# MDR1986VE81 register map
Vendor: Milandr; Series: ARMCM4; File version: 2.0
CPU: CM4 r0p0, little endian, MPU, FPU, 3 interrupt priority bits
Registers are 32-bit, read-write, reset 0x0 unless marked. A register's access mark holds for its fields unless they carry their own. Offsets are from the block's base; [hi:lo] are bit positions; {n}, {i} and the like mark numbered series; 'fields as' and 'values as' point back to an identical list.

## MDR_SRAM — OTP_SRAM Memory Control
Base 0x40006000
0x00 KEY — Unlock block register
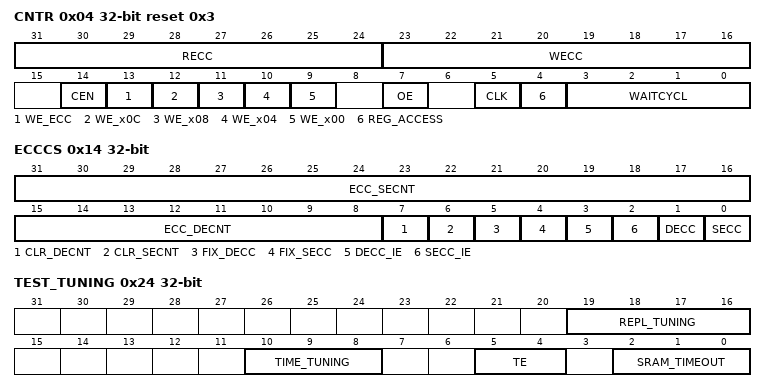
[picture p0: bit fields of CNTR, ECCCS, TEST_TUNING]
0x04 CNTR reset 0x3 — Control register
  [31:24] RECC — ECC after read with RDATA
  [23:16] WECC — ECC for write with WDATA
  [14] CEN — CE for SRAM
    0=Active (Memory selected); 1=Ivactive (Memory not selected)
  [13] WE_ECC — WE for SRAM addr ECC
    0=Write Enable; 1=Ivactive (Write Disable)
  [12] WE_x0C — WE for SRAM addr section 0x0C
    0=Write Enable; 1=Ivactive (Write Disable)
  [11] WE_x08 — WE for SRAM addr section 0x08
    0=Write Enable; 1=Ivactive (Write Disable)
  [10] WE_x04 — WE for SRAM addr section 0x04
    0=Write Enable; 1=Ivactive (Write Disable)
  [9] WE_x00 — WE for SRAM addr section 0x00
    0=Write Enable; 1=Ivactive (Write Disable)
  [7] OE — OE for SRAM
    0=Read Enable; 1=Ivactive (Read Disable)
  [5] CLK — Rise front to write or read
    0=Low (Logic 0); 1=High (Logic 1)
  [4] REG_ACCESS — OTP Access Delay
    0=Off (Bus access); 1=On (Access through registers)
  [3:0] WAITCYCL — OTP Access Delay
    0=Forbiden value; 1=20MHz83 (Delay for clock up to 20.83 MHz); 2=41MHz66 (Delay for clock up to 41.66 MHz); 3=62MHz5 (Delay for clock up to 62.5 MHz); 4=83MHz33 (Delay for clock up to 83.33 MHz); 5=100MHz (Delay for clock up to 100 MHz)
0x08 ADR — Access address
0x0C WDATA — Data to write
0x10 RDATA — Read out data
0x14 ECCCS — Control-Status Register
  [31:16] ECC_SECNT — SE Events Counter
  [15:8] ECC_DECNT — DE Events Counter
  [7] CLR_DECNT — Clear DE counter
    0=Inactive (No Action); 1=Clear (Action)
  [6] CLR_SECNT — Clear SE counter
    0=Inactive (No Action); 1=Clear (Action)
  [5] FIX_DECC — Log DE to ECCADR, ECCDATA, ECCECC
    0=Off (Disable); 1=On (Enable)
  [4] FIX_SECC — Log SE to ECCADR, ECCDATA, ECCECC
    0=Off (Disable); 1=On (Enable)
  [3] DECC_IE — DoubleError IRQ Enable
    0=Off (Disable); 1=On (Enable)
  [2] SECC_IE — SingleError IRQ Enable
    0=Off (Disable); 1=On (Enable)
  [1] DECC — DoubleError flag
    0=Off (No Event detected); 1=On (Event detected)
  [0] SECC — SingleError flag
    0=Off (No Event detected); 1=On (Event detected)
0x18 ECCADR — Last error address without correction
0x1C ECCDATA — Last error data without correction
0x20 ECCECC (reset mask 0xFF) — Last error ECC without correction
0x24 TEST_TUNING (reset mask 0xF0733) — Access Memory Tuning register
  [19:16] REPL_TUNING — Bit Hi_Level Read Resistance
    0=Repl_EasyMax (Read Resistance); 1=Repl_Easy1 (Read Resistance); 2=Repl_Norm (Read Resistance); {v}=Repl_Hard{v-2} (Read Resistance) (v=3..14); 15=Repl_HardMax (Read Resistance)
  [10:8] TIME_TUNING — Timeouts to read bit
    0=Time_HardMax (Read Timeout); 1=Time_Hard2 (Read Timeout); 2=Time_Hard1 (Read Timeout); 3=Time_Norm (Read Timeout); 4=Time_Easy1 (Read Timeout); 5=Time_Easy2 (Read Timeout); 6=Time_Easy3 (Read Timeout); 7=Time_EasyMax (Read Timeout)
  [5:4] TE — Select Test Mode
    0=Off (Normal Operation); 1=Test_1 (Test Mode 1); 2=Test_2 (Test Mode 2); 3=Test_3 (Test Mode 3)
  [2:0] SRAM_TIMEOUT — Timeouts to read SRAM
    0=Time_HardMax (SRAM Read Timeout); 1=Time_Hard2 (SRAM Read Timeout); 2=Time_Norm (SRAM Read Timeout); {v}=Time_Easy{v-2} (SRAM Read Timeout) (v=3..6); 7=Time_EasyMax (SRAM Read Timeout)

## MDR_SSP1 — Synchronous Serial Port
Base 0x40095000
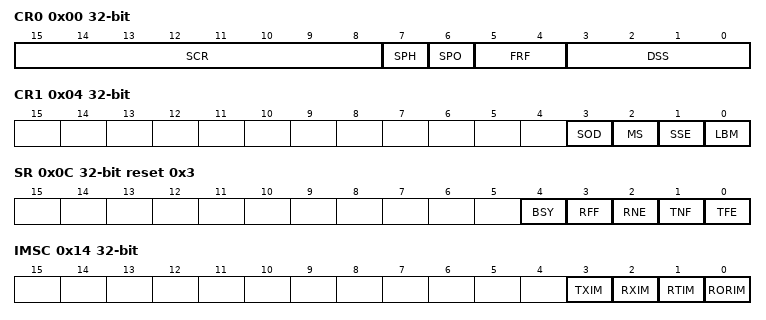
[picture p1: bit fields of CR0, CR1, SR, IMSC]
0x00 CR0 — Control Register 0
  [15:8] SCR — Signal CLock Rate
  [7] SPH — SPI Capture Clock Phase
    0=Leading (Capture data on leading edge); 1=Trailing (Capture data on trailing edge)
  [6] SPO — SPI Clock Polarity
    0=Idle_Low (Idle state is Low); 1=Idle_High (Idle state is High)
  [5:4] FRF — Frame Format
    0=SPI (Motorola SPI protocol); 1=SSI (Texas Instruments SSI protocol); 2=Microwire (National Semiconductor Microwire protocol)
  [3:0] DSS — Data Size Select
    {v}=bits_{v+1} (Word of {v+1} bits) (v=3..15)
0x04 CR1 — Control Register 1
  [3] SOD — Slave mode Output Disable
    0=SlaveTxEna (Slave mode transmit enable); 1=SlaveTxDis (Slave mode transmit disable)
  [2] MS — Master or Slave mode
    0=Master Mode; 1=Slave Mode
  [1] SSE — Synchronous Serial Enable
    0=Off (SSP Disable); 1=On (SSP Enable)
  [0] LBM — Loop Back Mode
    0=Normal operation; 1=LoopBack (TX send to RX test mode)
0x08 DR — FIFO_Rx and FIFO_Tx access
  [15:0] Data — Data value
0x0C SR ro reset 0x3 — Status Register
  [4] BSY — Transfer in progress
    0=Idle (FIFO_RX is Not Full); 1=Busy (Transfering)
  [3] RFF — FIFO_RX is Full
    0=RX_NotFull (FIFO_RX is Not Full); 1=RX_Full (FIFO_RX is Full)
  [2] RNE — FIFO_RX is Not Empty
    0=RX_NotEmpty (FIFO_RX is Empty); 1=RX_Empty (FIFO_RX is Not Empty)
  [1] TNF — FIFO_TX is Not Full
    0=TX_Full (FIFO_TX is Full); 1=TX_NotFull (FIFO_TX is Not Full)
  [0] TFE — FIFO_TX is Empty
    0=TX_NotEmpty (FIFO_TX is Not Empty); 1=TX_Empty (FIFO_TX is Empty)
0x10 CPSR — Clock Prescaller Register
  [7:0] CPSDVSR — Clock Prescaller
0x14 IMSC — IRQ Mask Set-Clear
  [3] TXIM — Enable IQR on FIFO_TX le 4 words
    0=NoEvent (Flag Inactive); 1=TX_HalfEmpty (Flag Active)
  [2] RXIM — Enable IQR on FIFO_RX ge 4 words
    0=NoEvent (Flag Inactive); 1=RX_HalfFull (Flag Active)
  [1] RTIM — Enable IQR on RX timeout for 32bits
    0=NoEvent (Flag Inactive); 1=RX_Timeout (Flag Active)
  [0] RORIM — Enable IRQ on FIFO_RX overrun
    0=NoEvent (Flag Inactive); 1=RX_Overrun (Flag Active)
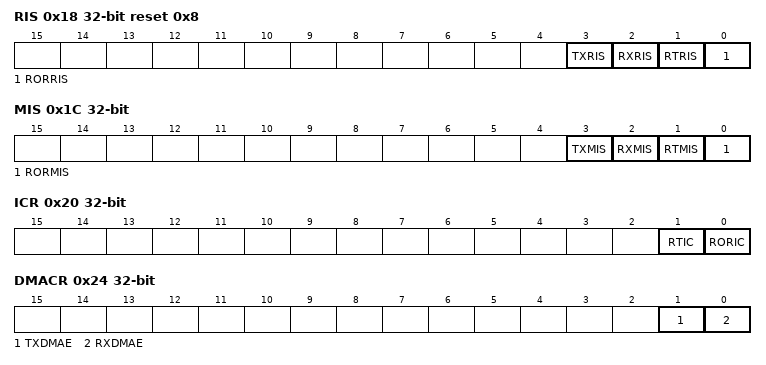
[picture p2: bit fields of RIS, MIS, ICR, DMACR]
0x18 RIS ro reset 0x8 — Raw Interupt Status
  [3] TXRIS — FIFO_TX le words
    0=NoEvent (Flag Inactive); 1=TX_HalfEmpty (Flag Active)
  [2] RXRIS — FIFO_RX gt words
    0=NoEvent (Flag Inactive); 1=RX_HalfFull (Flag Active)
  [1] RTRIS — RX timeout for 32bits
    0=NoEvent (Flag Inactive); 1=RX_Timeout (Flag Active)
  [0] RORRIS — FIFO_RX is overrun
    0=NoEvent (Flag Inactive); 1=RX_Overrun (Flag Active)
0x1C MIS ro — Masked Interupt Status
  [3] TXMIS — FIFO_TX le 4 words
    0=NoEvent (Flag Inactive); 1=TX_HalfEmpty (Flag Active)
  [2] RXMIS — FIFO_RX ge 4 words
    0=NoEvent (Flag Inactive); 1=RX_HalfFull (Flag Active)
  [1] RTMIS — RX timeout for 32bits
    0=NoEvent (Flag Inactive); 1=RX_Timeout (Flag Active)
  [0] RORMIS — FIFO_RX is overrun
    0=NoEvent (Flag Inactive); 1=RX_Overrun (Flag Active)
0x20 ICR wo — Interupt Clear Register
  [1] RTIC — Clear RX timeout flag
    0=Inactive (No action); 1=Clear Flag
  [0] RORIC — Clear FIFO_RX overrun flag
    0=Inactive (No action); 1=Clear Flag
0x24 DMACR — DMA Control Register
  [1] TXDMAE — Enable DMA by FIFO_TX not Full
    0=Disable DMA; 1=Enable DMA
  [0] RXDMAE — Enable DMA by FIFO_RX has data
    0=Disable DMA; 1=Enable DMA

## MDR_DMA — DMA Controler
Base 0xE0042000
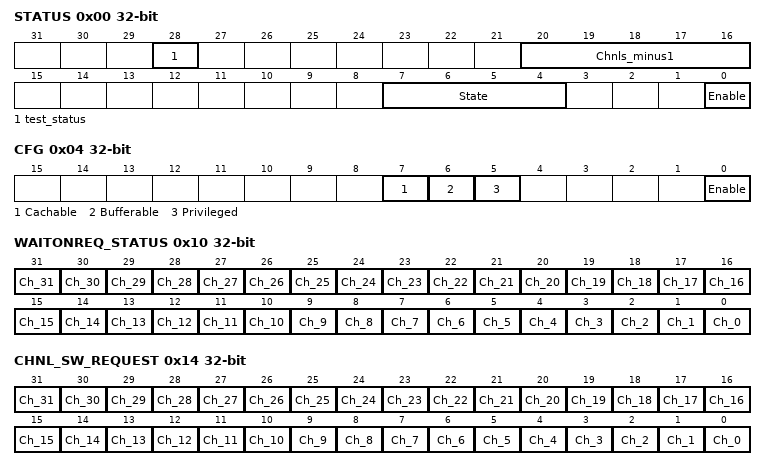
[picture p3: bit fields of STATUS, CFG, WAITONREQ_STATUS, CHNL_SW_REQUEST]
0x00 STATUS ro (reset mask 0xF01F0F01)
  [28] test_status — Test logic availability
    0=Unavailable (Test logic unavailable); 1=Available (Test logic available)
  [20:16] Chnls_minus1 — Channels count
    {v}={v+1}_channels (Channels Count) (v=0..31)
  [7:4] State — Active Operation
    0=Idle state; 1=RD_Ctrl (Reading channel controller data); 2=RD_pSrc (Reading source data end pointer); 3=RD_pDest (Reading destination data end pointer); 4=RD_Data (Reading source data); 5=WR_Data (writing destination data); 6=Wait_Clr (Waiting for DMA request to clear); 7=WR_Ctrl (Writing channel controller data); 8=Stalled transfer; 9=Done transfer; 10=ScatGath (scatter-gather transition)
  [0] Enable — Enable block
    0=Disabled (Block inactive); 1=Enabled (Block active)
0x04 CFG wo — Config register
  [7] Cachable — Cachable AHB bus priority
    0=Off (Inactive); 1=On (Active)
  [6] Bufferable — Bufferable AHB bus priority
    0=Off (Inactive); 1=On (Active)
  [5] Privileged — Privileged AHB bus priority
    0=Off (Inactive); 1=On (Active)
  [0] Enable — Enable block
    0=Disabled (Block inactive); 1=Enabled (Block active)
0x08 CTRL_BASE_PTR — Channel control data base pointer
  [31:10] Addr_Hi — Pointer
0x0C ALT_CTRL_BASE_PTR ro (reset mask 0xFFFFFC00) — Channel alternate control data base pointer
  [31:0] Addr — Pointer
0x10 WAITONREQ_STATUS ro — Channel wait on request status
  [n] Ch_{n} (n=0..31) — Channel Select
    0=Off (Inactive); 1=On (Active)
0x14 CHNL_SW_REQUEST wo write-1-sets — Channel Software Request
  fields as WAITONREQ_STATUS
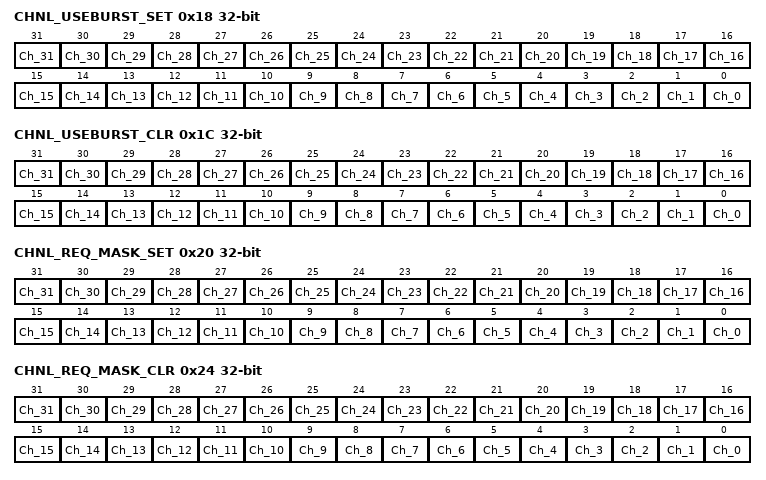
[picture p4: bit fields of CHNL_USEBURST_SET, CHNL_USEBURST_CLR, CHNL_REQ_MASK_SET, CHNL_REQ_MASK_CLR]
0x18 CHNL_USEBURST_SET write-1-sets — Disable SREQ requests
  fields as WAITONREQ_STATUS
0x1C CHNL_USEBURST_CLR wo write-1-clears — Enable SREQ requests
  fields as WAITONREQ_STATUS
0x20 CHNL_REQ_MASK_SET write-1-sets — Disable channel processing
  fields as WAITONREQ_STATUS
0x24 CHNL_REQ_MASK_CLR wo write-1-clears — Enable channel processing
  fields as WAITONREQ_STATUS
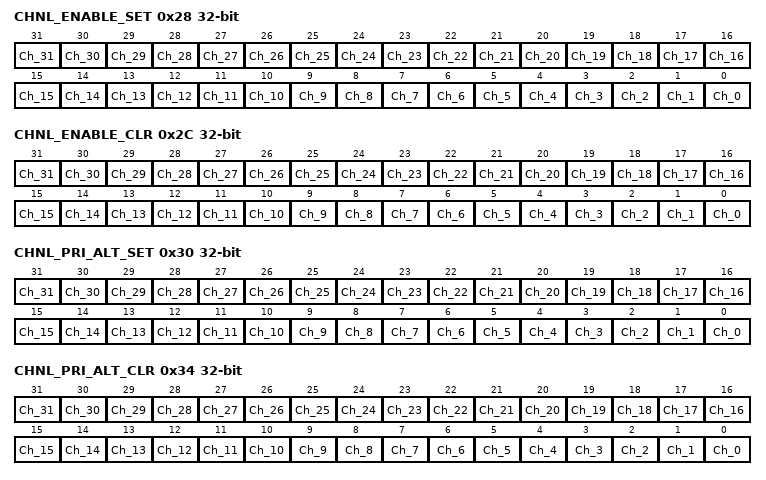
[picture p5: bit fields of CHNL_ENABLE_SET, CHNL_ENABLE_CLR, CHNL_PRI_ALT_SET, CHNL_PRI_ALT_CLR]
0x28 CHNL_ENABLE_SET write-1-sets — Start Channel
  fields as WAITONREQ_STATUS
0x2C CHNL_ENABLE_CLR wo write-1-clears — Stop Channel
  fields as WAITONREQ_STATUS
0x30 CHNL_PRI_ALT_SET write-1-sets — Select Alter Structure
  fields as WAITONREQ_STATUS
0x34 CHNL_PRI_ALT_CLR wo write-1-clears — Select Primary Structure
  fields as WAITONREQ_STATUS
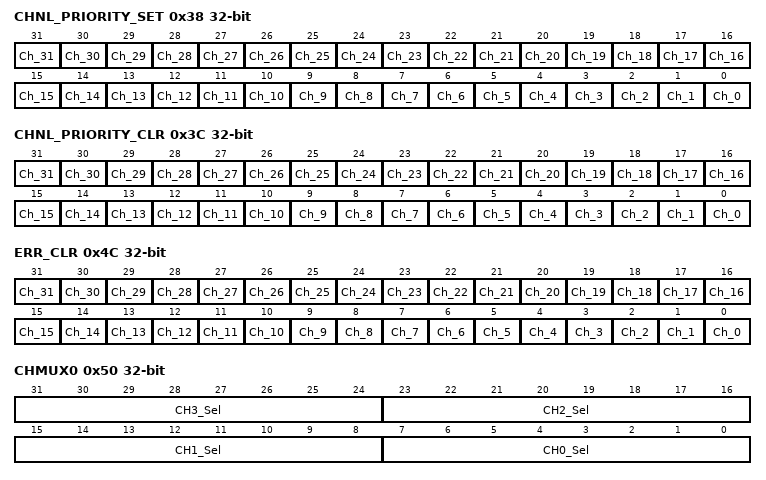
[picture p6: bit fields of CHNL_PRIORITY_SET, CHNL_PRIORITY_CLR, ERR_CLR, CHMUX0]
0x38 CHNL_PRIORITY_SET write-1-sets — Rise up priority to High
  fields as WAITONREQ_STATUS
0x3C CHNL_PRIORITY_CLR wo write-1-clears — Clear Priority to Normal
  fields as WAITONREQ_STATUS
0x4C ERR_CLR write-1-clears — AHB-Lite bus error clear
  fields as WAITONREQ_STATUS
0x50 CHMUX0 — Periph select for DMA channels 0..3
  [8n+7:8n] CH{n}_Sel (n=0..3) — Periph Event for DMA_Channel
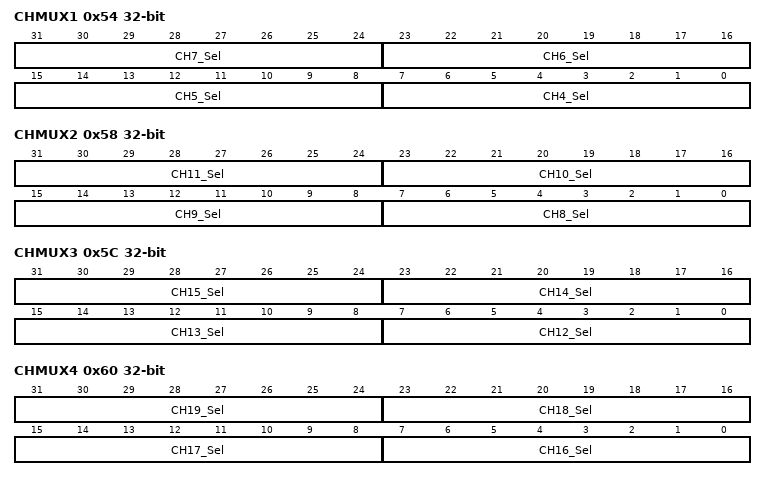
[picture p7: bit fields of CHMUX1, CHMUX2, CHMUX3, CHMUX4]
0x54 CHMUX1 — Periph select for DMA channels 4..7
  [8n-25:8n-32] CH{n}_Sel (n=4..7) — Periph Event for DMA_Channel
0x58 CHMUX2 — Periph select for DMA channels 8..11
  [8n-57:8n-64] CH{n}_Sel (n=8..11) — Periph Event for DMA_Channel
0x5C CHMUX3 — Periph select for DMA channels 12..15
  [8n-89:8n-96] CH{n}_Sel (n=12..15) — Periph Event for DMA_Channel
0x60 CHMUX4 — Periph select for DMA channels 16..19
  [8n-121:8n-128] CH{n}_Sel (n=16..19) — Periph Event for DMA_Channel
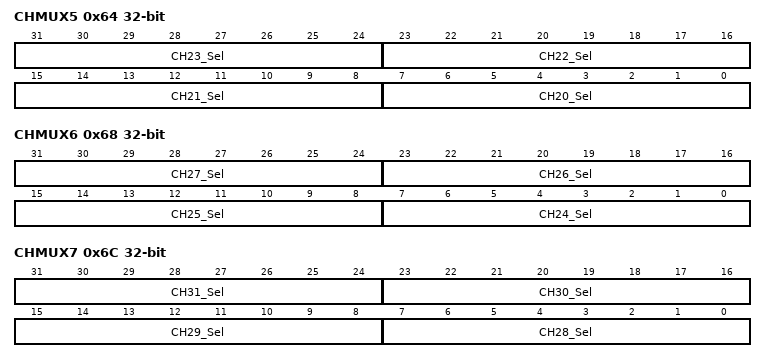
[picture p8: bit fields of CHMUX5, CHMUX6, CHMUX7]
0x64 CHMUX5 — Periph select for DMA channels 20..23
  [8n-153:8n-160] CH{n}_Sel (n=20..23) — Periph Event for DMA_Channel
0x68 CHMUX6 — Periph select for DMA channels 24..27
  [8n-185:8n-192] CH{n}_Sel (n=24..27) — Periph Event for DMA_Channel
0x6C CHMUX7 — Periph select for DMA channels 28..31
  [8n-217:8n-224] CH{n}_Sel (n=28..31) — Periph Event for DMA_Channel
